VERSION ""

NS_ :

BS_:

BU_: ELC ZGW

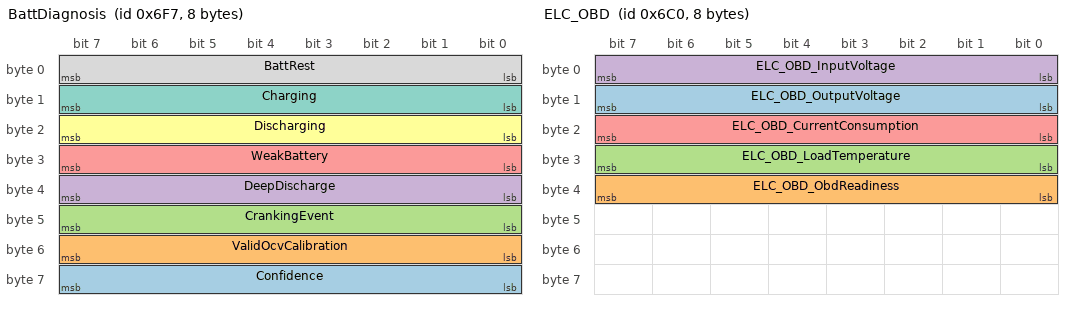
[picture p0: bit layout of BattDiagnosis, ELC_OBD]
BO_ 1783 BattDiagnosis: 8 ELC
 SG_ Confidence : 56|8@1+ (1,0) [0|255] ""  ZGW
 SG_ ValidOcvCalibration : 48|8@1+ (1,0) [0|255] ""  ZGW
 SG_ CrankingEvent : 40|8@1+ (1,0) [0|255] ""  ZGW
 SG_ DeepDischarge : 32|8@1+ (1,0) [0|255] ""  ZGW
 SG_ WeakBattery : 24|8@1+ (1,0) [0|255] ""  ZGW
 SG_ Discharging : 16|8@1+ (1,0) [0|255] ""  ZGW
 SG_ Charging : 8|8@1+ (1,0) [0|255] ""  ZGW
 SG_ BattRest : 0|8@1+ (1,0) [0|255] ""  ZGW

BO_ 1782 BattFullStat: 8 ELC
 SG_ TimeToFull : 32|32@1- (1,0) [-3.4E+38|3.4E+38] ""  ZGW
 SG_ RuntimeRemaining : 0|32@1- (1,0) [-3.4E+38|3.4E+38] ""  ZGW

BO_ 1781 BattCurrent: 8 ELC
 SG_ AvgDischargeCurrent : 32|32@1- (1,0) [-3.4E+38|3.4E+38] ""  ZGW
 SG_ AvgChargeCurrent : 0|32@1- (1,0) [-3.4E+38|3.4E+38] ""  ZGW

BO_ 1780 BattCapRes: 8 ELC
 SG_ IntResistance : 32|32@1- (1,0) [-3.4E+38|3.4E+38] ""  ZGW
 SG_ CapacityAh : 0|32@1- (1,0) [-3.4E+38|3.4E+38] ""  ZGW

BO_ 1779 BattSoCSoH: 8 ELC
 SG_ SoH : 32|32@1- (1,0) [-3.4E+38|3.4E+38] ""  ZGW
 SG_ SoC_Hybrid : 0|32@1- (1,0) [-3.4E+38|3.4E+38] ""  ZGW

BO_ 1778 BattSoC: 8 ELC
 SG_ SoC_OCV : 32|32@1- (1,0) [-3.4E+38|3.4E+38] ""  ZGW
 SG_ SoC_Coulomb : 0|32@1- (1,0) [-3.4E+38|3.4E+38] ""  ZGW

BO_ 1777 BattChargeDischarge: 8 ELC
 SG_ DischargeAh : 32|32@1- (1,0) [-3.4E+38|3.4E+38] ""  ZGW
 SG_ ChargeAh : 0|32@1- (1,0) [-3.4E+38|3.4E+38] ""  ZGW

BO_ 1728 ELC_OBD: 8 ELC
 SG_ ELC_OBD_OutputVoltage : 8|8@1+ (1,0) [0|255] ""  ZGW
 SG_ ELC_OBD_ObdReadiness : 32|8@1+ (1,0) [0|255] ""  ZGW
 SG_ ELC_OBD_LoadTemperature : 24|8@1+ (1,0) [-40|145] ""  ZGW
 SG_ ELC_OBD_InputVoltage : 0|8@1+ (1,0) [0|255] ""  ZGW
 SG_ ELC_OBD_CurrentConsumption : 16|8@1+ (1,0) [0|255] ""  ZGW

BO_ 1744 ZGW_CAN_3_OBD: 1 ZGW
 SG_ OBD_ObdReadiness : 0|8@1+ (1,0) [0|255] ""  ELC

BO_ 151 VehicleData: 1 ZGW
 SG_ VehicleStatus : 0|8@1+ (1,0) [0|15] ""  ELC

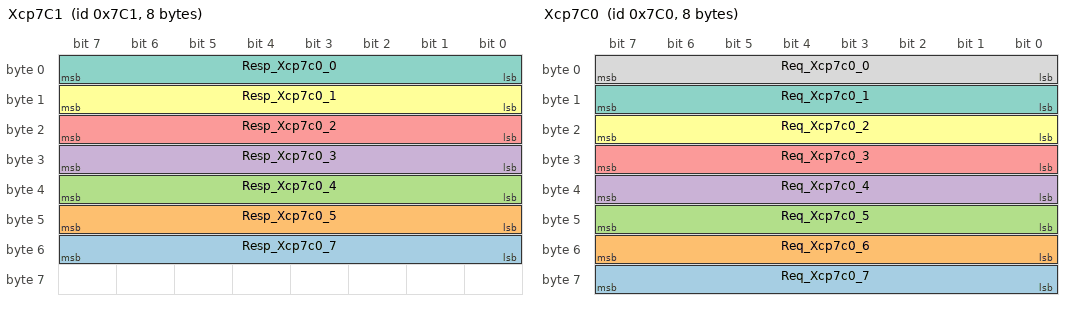
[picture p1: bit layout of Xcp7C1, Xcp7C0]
BO_ 1985 Xcp7C1: 8 ELC
 SG_ Resp_Xcp7c0_7 : 48|8@1+ (1,0) [0|255] ""  ZGW
 SG_ Resp_Xcp7c0_5 : 40|8@1+ (1,0) [0|255] ""  ZGW
 SG_ Resp_Xcp7c0_4 : 32|8@1+ (1,0) [0|255] ""  ZGW
 SG_ Resp_Xcp7c0_3 : 24|8@1+ (1,0) [0|255] ""  ZGW
 SG_ Resp_Xcp7c0_2 : 16|8@1+ (1,0) [0|255] ""  ZGW
 SG_ Resp_Xcp7c0_1 : 8|8@1+ (1,0) [0|255] ""  ZGW
 SG_ Resp_Xcp7c0_0 : 0|8@1+ (1,0) [0|255] ""  ZGW

BO_ 1984 Xcp7C0: 8 ELC
 SG_ Req_Xcp7c0_7 : 56|8@1+ (1,0) [0|255] ""  ELC
 SG_ Req_Xcp7c0_6 : 48|8@1+ (1,0) [0|255] ""  ELC
 SG_ Req_Xcp7c0_5 : 40|8@1+ (1,0) [0|255] ""  ELC
 SG_ Req_Xcp7c0_4 : 32|8@1+ (1,0) [0|255] ""  ELC
 SG_ Req_Xcp7c0_3 : 24|8@1+ (1,0) [0|255] ""  ELC
 SG_ Req_Xcp7c0_2 : 16|8@1+ (1,0) [0|255] ""  ELC
 SG_ Req_Xcp7c0_1 : 8|8@1+ (1,0) [0|255] ""  ELC
 SG_ Req_Xcp7c0_0 : 0|8@1+ (1,0) [0|255] ""  ELC

BO_ 1774 TempMeas: 8 ELC
 SG_ McuTemperature : 32|32@1- (1,0) [-3.4E+38|3.4E+38] ""  ZGW
 SG_ NTCTemperature_L1 : 0|32@1- (1,0) [-3.4E+38|3.4E+38] ""  ZGW

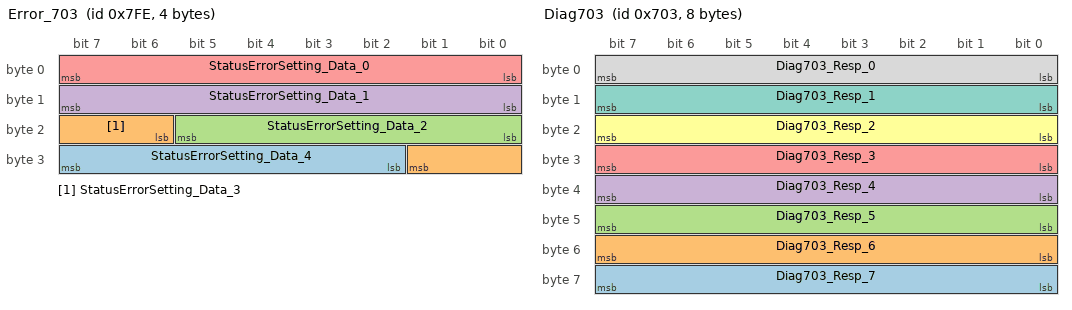
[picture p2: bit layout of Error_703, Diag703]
BO_ 2046 Error_703: 4 ELC
 SG_ StatusErrorSetting_Data_4 : 26|6@1+ (1,0) [0|63] ""  ZGW
 SG_ StatusErrorSetting_Data_3 : 22|4@1+ (1,0) [0|255] ""  ZGW
 SG_ StatusErrorSetting_Data_2 : 16|6@1+ (1,0) [0|255] ""  ZGW
 SG_ StatusErrorSetting_Data_1 : 8|8@1+ (1,0) [0|255] ""  ZGW
 SG_ StatusErrorSetting_Data_0 : 0|8@1+ (1,0) [0|255] ""  ZGW

BO_ 1023 NM3: 1 ZGW
 SG_ NM3S_PN1 : 0|8@1+ (1,0) [0|255] ""  ELC

BO_ 1795 Diag703: 8 ZGW
 SG_ Diag703_Resp_7 : 56|8@1+ (1,0) [0|255] ""  ZGW
 SG_ Diag703_Resp_6 : 48|8@1+ (1,0) [0|255] ""  ZGW
 SG_ Diag703_Resp_5 : 40|8@1+ (1,0) [0|255] ""  ZGW
 SG_ Diag703_Resp_4 : 32|8@1+ (1,0) [0|255] ""  ZGW
 SG_ Diag703_Resp_3 : 24|8@1+ (1,0) [0|255] ""  ZGW
 SG_ Diag703_Resp_2 : 16|8@1+ (1,0) [0|255] ""  ZGW
 SG_ Diag703_Resp_1 : 8|8@1+ (1,0) [0|255] ""  ZGW
 SG_ Diag703_Resp_0 : 0|8@1+ (1,0) [0|255] ""  ZGW

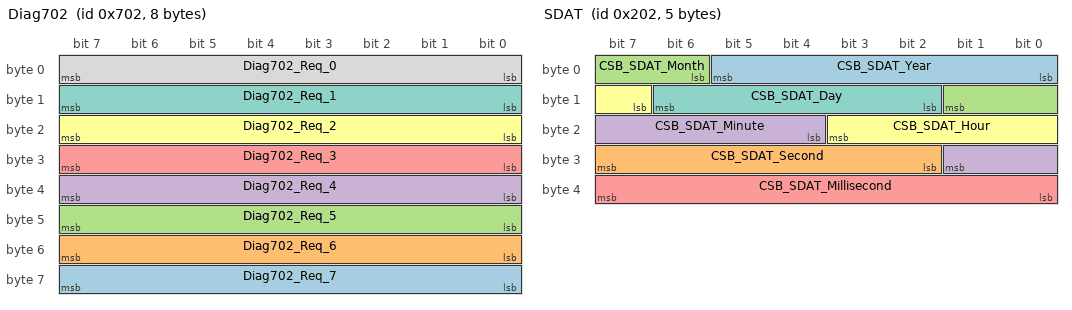
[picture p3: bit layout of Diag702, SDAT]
BO_ 1794 Diag702: 8 ZGW
 SG_ Diag702_Req_7 : 56|8@1+ (1,0) [0|255] ""  ELC
 SG_ Diag702_Req_6 : 48|8@1+ (1,0) [0|255] ""  ELC
 SG_ Diag702_Req_5 : 40|8@1+ (1,0) [0|255] ""  ELC
 SG_ Diag702_Req_4 : 32|8@1+ (1,0) [0|255] ""  ELC
 SG_ Diag702_Req_3 : 24|8@1+ (1,0) [0|255] ""  ELC
 SG_ Diag702_Req_2 : 16|8@1+ (1,0) [0|255] ""  ELC
 SG_ Diag702_Req_1 : 8|8@1+ (1,0) [0|255] ""  ELC
 SG_ Diag702_Req_0 : 0|8@1+ (1,0) [0|255] ""  ELC

BO_ 514 SDAT: 5 ZGW
 SG_ CSB_SDAT_Year : 0|6@1+ (1,0) [0|63] ""  ELC
 SG_ CSB_SDAT_Second : 26|6@1+ (1,0) [0|59] ""  ELC
 SG_ CSB_SDAT_Month : 6|4@1+ (1,0) [0|12] ""  ELC
 SG_ CSB_SDAT_Minute : 20|6@1+ (1,0) [0|59] ""  ELC
 SG_ CSB_SDAT_Millisecond : 32|8@1+ (1,0) [0|255] ""  ELC
 SG_ CSB_SDAT_Hour : 15|5@1+ (1,0) [0|24] ""  ELC
 SG_ CSB_SDAT_Day : 10|5@1+ (1,0) [0|31] ""  ELC

BO_ 1776 L1_I2TCounter: 4 ELC
 SG_ LoadTrace_I2TCounter : 0|32@1+ (1,0) [0|4294967295] ""  ZGW

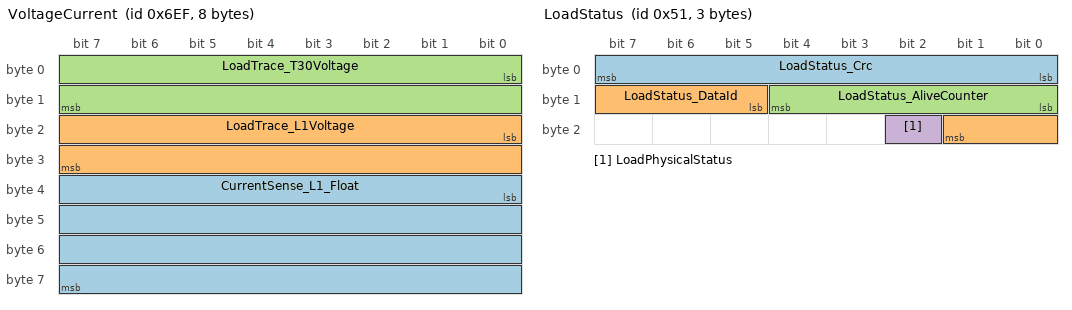
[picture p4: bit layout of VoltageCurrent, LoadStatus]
BO_ 1775 VoltageCurrent: 8 ELC
 SG_ CurrentSense_L1_Float : 32|32@1- (1,0) [-3.4E+38|3.4E+38] "" Vector__XXX
 SG_ LoadTrace_L1Voltage : 16|16@1+ (1,0) [0|65535] ""  ZGW
 SG_ LoadTrace_T30Voltage : 0|16@1+ (1,0) [0|65535] ""  ZGW

BO_ 81 LoadStatus: 3 ELC
 SG_ LoadStatus_Crc : 0|8@1+ (1,0) [0|255] "" Vector__XXX
 SG_ LoadStatus_DataId : 13|5@1+ (1,0) [21|21] "" Vector__XXX
 SG_ LoadStatus_AliveCounter : 8|5@1+ (1,0) [0|15] "" Vector__XXX
 SG_ LoadPhysicalStatus : 18|1@1+ (1,0) [0|1] ""  ZGW

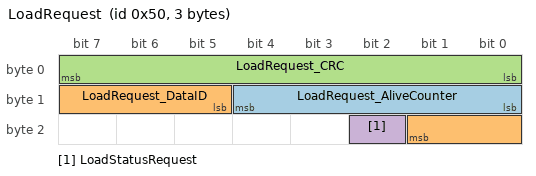
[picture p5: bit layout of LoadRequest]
BO_ 80 LoadRequest: 3 ZGW
 SG_ LoadRequest_AliveCounter : 8|5@1+ (1,0) [0|15] "" Vector__XXX
 SG_ LoadRequest_DataID : 13|5@1+ (1,0) [21|21] "" Vector__XXX
 SG_ LoadRequest_CRC : 0|8@1+ (1,0) [0|255] "" Vector__XXX
 SG_ LoadStatusRequest : 18|1@1+ (1,0) [0|1] ""  ELC

BA_DEF_  "BusType" STRING ;
BA_DEF_DEF_  "BusType" "CAN";
SIG_VALTYPE_ 1782 TimeToFull : 1;
SIG_VALTYPE_ 1782 RuntimeRemaining : 1;
SIG_VALTYPE_ 1781 AvgDischargeCurrent : 1;
SIG_VALTYPE_ 1781 AvgChargeCurrent : 1;
SIG_VALTYPE_ 1780 IntResistance : 1;
SIG_VALTYPE_ 1780 CapacityAh : 1;
SIG_VALTYPE_ 1779 SoH : 1;
SIG_VALTYPE_ 1779 SoC_Hybrid : 1;
SIG_VALTYPE_ 1778 SoC_OCV : 1;
SIG_VALTYPE_ 1778 SoC_Coulomb : 1;
SIG_VALTYPE_ 1777 DischargeAh : 1;
SIG_VALTYPE_ 1777 ChargeAh : 1;
SIG_VALTYPE_ 1774 McuTemperature : 1;
SIG_VALTYPE_ 1774 NTCTemperature_L1 : 1;
SIG_VALTYPE_ 1775 CurrentSense_L1_Float : 1;
